AUTOSAR XML (schema 4-0-3)
package /ComponentTypes
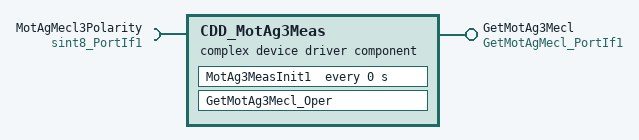
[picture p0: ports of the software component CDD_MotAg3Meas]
  complex device driver sw component type CDD_MotAg3Meas
    provide port GetMotAg3Mecl: server-com-spec{operation=Oper, queue-length=1}, provided-interface=GetMotAgMecl_PortIf1
    require port MotAgMecl3Polarity: nonqueued-receiver-com-spec{data-element=Val, filter=data-filter-type=ALWAYS, init-value=1}, required-interface=sint8_PortIf1  # Polarity value of Motor Angle 3
    behavior CDD_MotAg3Meas_InternalBehavior
      operation invoked event OIT_GetMotAg3Mecl_Oper_GetMotAg3Mecl_Oper: start-on-event=GetMotAg3Mecl_Oper, operation=GetMotAg3Mecl.Oper
      timing event CDD_MotAg3Meas_InitEvent: start-on-event=MotAg3MeasInit1, period=0
      runnable GetMotAg3Mecl_Oper
        data-receive-point-by-arguments:
          access REC_MotAgMecl3Polarity_Val: accessed-variable=MotAgMecl3Polarity.Val
      runnable MotAg3MeasInit1  # Initial Function for Motor Angle 3 Measurement
  swc implementation CDD_MotAg3Meas_Implementation: behavior=CDD_MotAg3Meas_InternalBehavior
    code-descriptors:
      code Default: artifact-descriptors=autosar-engineering-object={short-label=Default, category=SWSRC}
